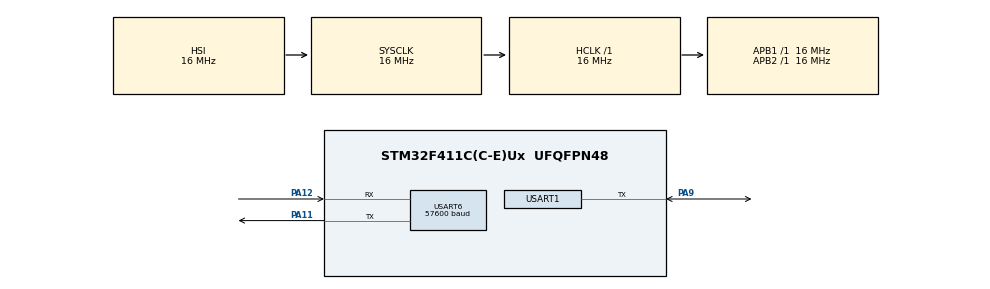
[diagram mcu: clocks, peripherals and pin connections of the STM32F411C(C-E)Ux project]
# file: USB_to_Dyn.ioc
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Dma.Request0=USART6_TX
Dma.USART6_TX.0.Direction=DMA_MEMORY_TO_PERIPH
Dma.USART6_TX.0.FIFOMode=DMA_FIFOMODE_DISABLE
Dma.USART6_TX.0.Instance=DMA2_Stream6
Dma.USART6_TX.0.MemDataAlignment=DMA_MDATAALIGN_BYTE
Dma.USART6_TX.0.MemInc=DMA_MINC_ENABLE
Dma.USART6_TX.0.Mode=DMA_NORMAL
Dma.USART6_TX.0.PeriphDataAlignment=DMA_PDATAALIGN_BYTE
Dma.USART6_TX.0.PeriphInc=DMA_PINC_DISABLE
Dma.USART6_TX.0.Priority=DMA_PRIORITY_LOW
Mcu.Family=STM32F4
Mcu.Name=STM32F411C(C-E)Ux
Mcu.Package=UFQFPN48
NVIC.DMA2_Stream6_IRQn=true\:0\:0\:false\:false\:true\:false\:true\:true
NVIC.PriorityGroup=NVIC_PRIORITYGROUP_4
NVIC.USART1_IRQn=true\:0\:0\:false\:false\:true\:true\:true\:true
NVIC.USART6_IRQn=true\:0\:0\:false\:false\:true\:true\:true\:true
PA11.Mode=Asynchronous
PA11.Signal=USART6_TX
PA12.Mode=Asynchronous
PA12.Signal=USART6_RX
PA13.Mode=Serial_Wire
PA13.Signal=SYS_JTMS-SWDIO
PA14.Mode=Serial_Wire
PA14.Signal=SYS_JTCK-SWCLK
PA9.Mode=Half_duplex(single_wire_mode)
PA9.Signal=USART1_TX
ProjectManager.HeapSize=0x200
ProjectManager.StackSize=0x400
ProjectManager.TargetToolchain=MDK-ARM V5.32
RCC.AHBFreq_Value=16000000
RCC.APB1Freq_Value=16000000
RCC.APB2Freq_Value=16000000
RCC.CortexFreq_Value=16000000
RCC.HSE_VALUE=25000000
RCC.HSI_VALUE=16000000
RCC.LSE_VALUE=32768
RCC.SYSCLKFreq_VALUE=16000000
RCC.VCOOutputFreq_Value=192000000
USART1.BaudRate=56700
USART1.VirtualMode=VM_ASYNC
USART6.BaudRate=57600
USART6.VirtualMode=VM_ASYNC
board=custom

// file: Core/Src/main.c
/* USER CODE BEGIN Header */
/**
  ******************************************************************************
  * @file           : main.c
  * @brief          : Main program body
  ******************************************************************************
  * @attention
  *
  * Copyright (c) 2023 STMicroelectronics.
  * All rights reserved.
  *
  * This software is licensed under terms that can be found in the LICENSE file
  * in the root directory of this software component.
  * If no LICENSE file comes with this software, it is provided AS-IS.
  *
  ******************************************************************************
  */
/* USER CODE END Header */
#include "main.h"

/* USER CODE BEGIN PTD */
	uint8_t BufOut[20];
	uint8_t BufIn[300];
	uint8_t flag;
	uint8_t length;
/* USER CODE END PTD */

UART_HandleTypeDef huart1;
UART_HandleTypeDef huart6;
DMA_HandleTypeDef hdma_usart6_tx;

void SystemClock_Config(void);
static void MX_GPIO_Init(void);
static void MX_DMA_Init(void);
static void MX_USART1_UART_Init(void);
static void MX_USART6_UART_Init(void);

int main(void)
{

  /* MCU Configuration--------------------------------------------------------*/

  /* Reset of all peripherals, Initializes the Flash interface and the Systick. */
  HAL_Init();

  /* Configure the system clock */
  SystemClock_Config();

  /* Initialize all configured peripherals */
  MX_GPIO_Init();
  MX_DMA_Init();
  MX_USART1_UART_Init();
  MX_USART6_UART_Init();
  /* USER CODE BEGIN 2 */
	HAL_HalfDuplex_EnableTransmitter(&huart1);
//	HAL_UART_Transmit(&huart1, BufOut, 5,1000);
/*BufIn[0]=0xFF;
BufIn[1]=0xFF;
BufIn[2]=0x2;
BufIn[3]=0x9;
BufIn[4]=0x0;
BufIn[5]=0x1D;
BufIn[6]=0x0;
BufIn[7]=0x29;
BufIn[8]=0x02;
BufIn[9]=0x22;
BufIn[10]=0xFA;
BufIn[11]=0x00;
BufIn[12]=0x90;*/
  /* USER CODE END 2 */

  /* Infinite loop */
  /* USER CODE BEGIN WHILE */
  while (1)
  {

		if((flag&(1<<RecieveOk))!=0)
		{
			HAL_HalfDuplex_EnableTransmitter(&huart1);
			HAL_UART_Transmit(&huart1, BufOut, 1+length,1000);
			if (BufOut[4]!=1)
			{
				length=BufOut[length-1]+6;
			}
			else
			{
				length=BufOut[length-1]+5;
			}
			HAL_HalfDuplex_EnableReceiver(&huart1);
			HAL_UART_Receive(&huart1,BufIn ,length,100);//BufOut[length-1]+5,100);
			HAL_UART_Transmit(&huart6,BufIn,length,length*30);//BufOut[length-1]+5,100);
			flag&=~(1<<RecieveOk);
		}
    /* USER CODE END WHILE */

  }
}

void SystemClock_Config(void)
{
  RCC_OscInitTypeDef RCC_OscInitStruct = {0};
  RCC_ClkInitTypeDef RCC_ClkInitStruct = {0};

  /** Configure the main internal regulator output voltage
  */
  __HAL_RCC_PWR_CLK_ENABLE();
  __HAL_PWR_VOLTAGESCALING_CONFIG(PWR_REGULATOR_VOLTAGE_SCALE1);

  /** Initializes the RCC Oscillators according to the specified parameters
  * in the RCC_OscInitTypeDef structure.
  */
  RCC_OscInitStruct.OscillatorType = RCC_OSCILLATORTYPE_HSI;
  RCC_OscInitStruct.HSIState = RCC_HSI_ON;
  RCC_OscInitStruct.HSICalibrationValue = RCC_HSICALIBRATION_DEFAULT;
  RCC_OscInitStruct.PLL.PLLState = RCC_PLL_NONE;
  if (HAL_RCC_OscConfig(&RCC_OscInitStruct) != HAL_OK)
  {
    Error_Handler();
  }

  /** Initializes the CPU, AHB and APB buses clocks
  */
  RCC_ClkInitStruct.ClockType = RCC_CLOCKTYPE_HCLK|RCC_CLOCKTYPE_SYSCLK
                              |RCC_CLOCKTYPE_PCLK1|RCC_CLOCKTYPE_PCLK2;
  RCC_ClkInitStruct.SYSCLKSource = RCC_SYSCLKSOURCE_HSI;
  RCC_ClkInitStruct.AHBCLKDivider = RCC_SYSCLK_DIV1;
  RCC_ClkInitStruct.APB1CLKDivider = RCC_HCLK_DIV1;
  RCC_ClkInitStruct.APB2CLKDivider = RCC_HCLK_DIV1;

  if (HAL_RCC_ClockConfig(&RCC_ClkInitStruct, FLASH_LATENCY_0) != HAL_OK)
  {
    Error_Handler();
  }
}

static void MX_USART1_UART_Init(void)
{

  huart1.Instance = USART1;
  huart1.Init.BaudRate = 56700;
  huart1.Init.WordLength = UART_WORDLENGTH_8B;
  huart1.Init.StopBits = UART_STOPBITS_1;
  huart1.Init.Parity = UART_PARITY_NONE;
  huart1.Init.Mode = UART_MODE_TX_RX;
  huart1.Init.HwFlowCtl = UART_HWCONTROL_NONE;
  huart1.Init.OverSampling = UART_OVERSAMPLING_16;
  if (HAL_HalfDuplex_Init(&huart1) != HAL_OK)
  {
    Error_Handler();
  }

}

static void MX_USART6_UART_Init(void)
{

  huart6.Instance = USART6;
  huart6.Init.BaudRate = 57600;
  huart6.Init.WordLength = UART_WORDLENGTH_8B;
  huart6.Init.StopBits = UART_STOPBITS_1;
  huart6.Init.Parity = UART_PARITY_NONE;
  huart6.Init.Mode = UART_MODE_TX_RX;
  huart6.Init.HwFlowCtl = UART_HWCONTROL_NONE;
  huart6.Init.OverSampling = UART_OVERSAMPLING_16;
  if (HAL_UART_Init(&huart6) != HAL_OK)
  {
    Error_Handler();
  }
  /* USER CODE BEGIN USART6_Init 2 */
	NVIC_EnableIRQ(USART6_IRQn);
	USART6->CR1|=USART_CR1_RXNEIE|USART_CR1_RE;
  /* USER CODE END USART6_Init 2 */

}

static void MX_DMA_Init(void)
{

  /* DMA controller clock enable */
  __HAL_RCC_DMA2_CLK_ENABLE();

  /* DMA interrupt init */
  /* DMA2_Stream6_IRQn interrupt configuration */
  HAL_NVIC_SetPriority(DMA2_Stream6_IRQn, 0, 0);
  HAL_NVIC_EnableIRQ(DMA2_Stream6_IRQn);

}

static void MX_GPIO_Init(void)
{

  /* GPIO Ports Clock Enable */
  __HAL_RCC_GPIOA_CLK_ENABLE();

}

void Error_Handler(void)
{
  __disable_irq();
  while (1)
  {
  }
}
